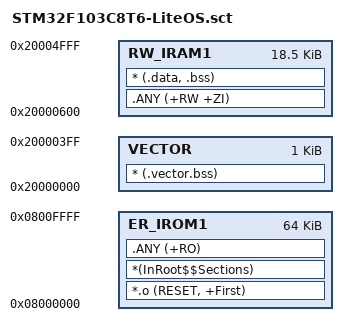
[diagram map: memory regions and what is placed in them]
; *************************************************************
; *** Scatter-Loading Description File generated by uVision ***
; *************************************************************

LR_IROM1 0x08000000 0x00010000  {    ; load region size_region 64k
  ER_IROM1 0x08000000 0x00010000  {  ; load address = execution address
   *.o (RESET, +First)
   *(InRoot$$Sections)
   .ANY (+RO)
  }
  VECTOR 0x20000000 0x400 { ;vector
	* (.vector.bss)
  }

  RW_IRAM1 0x20000600 0x00004A00  {  ; RW data Total 0x5000  0x5000 - 0x600 = 0x4A00
   .ANY (+RW +ZI)
   * (.data, .bss)
  }
}

